AUTOSAR XML (schema 4.0)
standard types defined: float32, float64, sint16, sint32, sint8, uint16, uint32, uint8, void, boolean
package /ImplDataTypes
  impl type Impl_MultiStateBtnType: implementation-data-type=uint8, type-emitter=RTE
  impl type Impl_StepMotorStepType: implementation-data-type=uint8, type-emitter=RTE
package /MappingSets
  data type mapping set MappingSet
package /PortInterfaces/ClientServer
  client server interface CsIf_StepMotor
    operation Opr_Move
      arg Arg_step: type=Impl_StepMotorStepType, direction=IN
package /PortInterfaces/SenderReceiver
  sender receiver interface SrIf_SeatCtrlBtns
    data DE_HeightBtnState: type=Impl_MultiStateBtnType
    data DE_InclineBtnState: type=Impl_MultiStateBtnType
    data DE_SlideBtnState: type=Impl_MultiStateBtnType
  sender receiver interface SrIf_SeatCtrlData
    data DE_Height: type=uint8
    data DE_Incline: type=uint8
    data DE_Slide: type=uint8
package /SoftwareComponents
  5 x swc implementation, all with programming-language=C, sw-version=1.0.0, vendor-id=255:
    Impl_SWC_HMI: behavior=Ibhv_SWC_HMI
      code-descriptors:
        code Code: artifact-descriptors=autosar-engineering-object={short-label=SWC.c, category=SWSRC}
      resource consumption ResourceConsumption
    Impl_SWC_HeightMotor: behavior=Ibhv_SWC_HeightMotor
      code-descriptors:
        code Code: artifact-descriptors=autosar-engineering-object={short-label=SWC.c, category=SWSRC}
      resource consumption ResourceConsumption
    Impl_SWC_InclineMotor: behavior=Ibhv_SWC_InclineMotor
      code-descriptors:
        code Code: artifact-descriptors=autosar-engineering-object={short-label=SWC.c, category=SWSRC}
      resource consumption ResourceConsumption
    Impl_SWC_Seat_Manger: behavior=Ibhv_SWC_Seat_Manger
      code-descriptors:
        code Code: artifact-descriptors=autosar-engineering-object={short-label=SWC.c, category=SWSRC}
      resource consumption ResourceConsumption
    Impl_SWC_SlideMotor: behavior=Ibhv_SWC_SlideMotor
      code-descriptors:
        code Code: artifact-descriptors=autosar-engineering-object={short-label=SWC.c, category=SWSRC}
      resource consumption ResourceConsumption
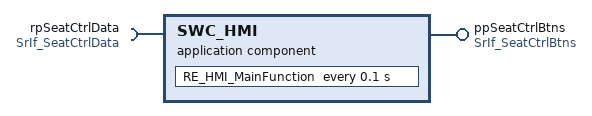
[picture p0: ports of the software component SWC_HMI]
  application sw component type SWC_HMI
    provide port ppSeatCtrlBtns: provided-interface=SrIf_SeatCtrlBtns
    require port rpSeatCtrlData: required-interface=SrIf_SeatCtrlData
    behavior Ibhv_SWC_HMI: data-type-mapping=MappingSet, handle-termination-and-restart=NO-SUPPORT
      timing event TE_RE_HMI_MainFunction_100ms: start-on-event=RE_HMI_MainFunction, period=0.1
      runnable RE_HMI_MainFunction
        data-receive-point-by-arguments:
          access DRP_rpSeatCtrlData_DE_Height: accessed-variable=rpSeatCtrlData.DE_Height
          access DRP_rpSeatCtrlData_DE_Incline: accessed-variable=rpSeatCtrlData.DE_Incline
          access DRP_rpSeatCtrlData_DE_Slide: accessed-variable=rpSeatCtrlData.DE_Slide
        data-send-points:
          access DSP_ppSeatCtrlBtns_DE_HeightBtnState: accessed-variable=ppSeatCtrlBtns.DE_HeightBtnState
          access DSP_ppSeatCtrlBtns_DE_InclineBtnState: accessed-variable=ppSeatCtrlBtns.DE_InclineBtnState
          access DSP_ppSeatCtrlBtns_DE_SlideBtnState: accessed-variable=ppSeatCtrlBtns.DE_SlideBtnState
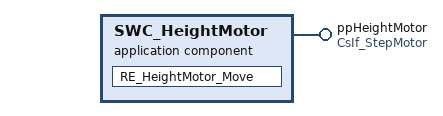
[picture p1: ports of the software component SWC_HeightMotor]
  application sw component type SWC_HeightMotor
    provide port ppHeightMotor: provided-interface=CsIf_StepMotor
    behavior Ibhv_SWC_HeightMotor: data-type-mapping=MappingSet, handle-termination-and-restart=NO-SUPPORT
      operation invoked event OIE_ppHeightMotor_Opr_Move: start-on-event=RE_HeightMotor_Move, operation=ppHeightMotor.Opr_Move
      runnable RE_HeightMotor_Move
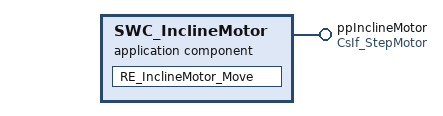
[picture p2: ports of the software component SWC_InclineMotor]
  application sw component type SWC_InclineMotor
    provide port ppInclineMotor: provided-interface=CsIf_StepMotor
    behavior Ibhv_SWC_InclineMotor: data-type-mapping=MappingSet, handle-termination-and-restart=NO-SUPPORT
      operation invoked event OIE_ppInclineMotor_Opr_Move: start-on-event=RE_InclineMotor_Move, operation=ppInclineMotor.Opr_Move
      runnable RE_InclineMotor_Move
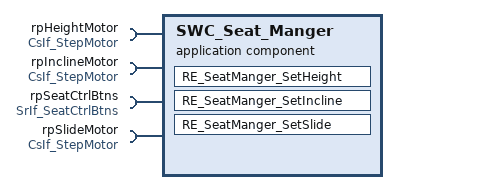
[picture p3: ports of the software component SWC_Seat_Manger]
  application sw component type SWC_Seat_Manger
    4 x require port:
      rpHeightMotor: required-interface=CsIf_StepMotor
      rpInclineMotor: required-interface=CsIf_StepMotor
      rpSeatCtrlBtns: required-interface=SrIf_SeatCtrlBtns
      rpSlideMotor: required-interface=CsIf_StepMotor
    behavior Ibhv_SWC_Seat_Manger: data-type-mapping=MappingSet, handle-termination-and-restart=NO-SUPPORT
      data received event DRE_rpSeatCtrlBtns_DE_HeightBtnState: start-on-event=RE_SeatManger_SetHeight, data=rpSeatCtrlBtns.DE_HeightBtnState
      data received event DRE_rpSeatCtrlBtns_DE_InclineBtnState: start-on-event=RE_SeatManger_SetIncline, data=rpSeatCtrlBtns.DE_InclineBtnState
      data received event DRE_rpSeatCtrlBtns_DE_SlideBtnState: start-on-event=RE_SeatManger_SetSlide, data=rpSeatCtrlBtns.DE_SlideBtnState
      runnable RE_SeatManger_SetHeight
        data-receive-point-by-arguments:
          access DRP_rpSeatCtrlBtns_DE_HeightBtnState: accessed-variable=rpSeatCtrlBtns.DE_HeightBtnState
        sync call SCP_rpHeightMotor_Opr_Move: operation=rpHeightMotor.Opr_Move, timeout=0.0
      runnable RE_SeatManger_SetIncline
        data-receive-point-by-arguments:
          access DRP_rpSeatCtrlBtns_DE_InclineBtnState: accessed-variable=rpSeatCtrlBtns.DE_InclineBtnState
        sync call SCP_rpInclineMotor_Opr_Move: operation=rpInclineMotor.Opr_Move, timeout=0.0
      runnable RE_SeatManger_SetSlide
        data-receive-point-by-arguments:
          access DRP_rpSeatCtrlBtns_DE_SlideBtnState: accessed-variable=rpSeatCtrlBtns.DE_SlideBtnState
        sync call SCP_rpSlideMotor_Opr_Move: operation=rpSlideMotor.Opr_Move, timeout=0.0
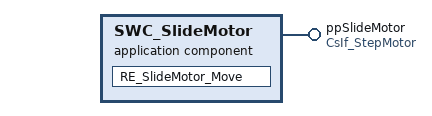
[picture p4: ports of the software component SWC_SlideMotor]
  application sw component type SWC_SlideMotor
    provide port ppSlideMotor: provided-interface=CsIf_StepMotor
    behavior Ibhv_SWC_SlideMotor: data-type-mapping=MappingSet, handle-termination-and-restart=NO-SUPPORT
      operation invoked event OIE_ppSlideMotor_Opr_Move: start-on-event=RE_SlideMotor_Move, operation=ppSlideMotor.Opr_Move
      runnable RE_SlideMotor_Move
package /Compositions
  composition sw component type SeatAdjManger_task2_AutoSAR_SprintsComposition
    5 x component:
      SWC_HMI: type=SWC_HMI
      SWC_HeightMotor: type=SWC_HeightMotor
      SWC_InclineMotor: type=SWC_InclineMotor
      SWC_Seat_Manger: type=SWC_Seat_Manger
      SWC_SlideMotor: type=SWC_SlideMotor
    connect SWC_HMI.ppSeatCtrlBtns -> SWC_Seat_Manger.rpSeatCtrlBtns
    connect SWC_HeightMotor.ppHeightMotor -> SWC_Seat_Manger.rpHeightMotor
    connect SWC_InclineMotor.ppInclineMotor -> SWC_Seat_Manger.rpInclineMotor
    connect SWC_SlideMotor.ppSlideMotor -> SWC_Seat_Manger.rpSlideMotor
